AUTOSAR XML (schema 4-2-2)
standard types defined: uint8, uint16, sint8
package /AUTOSAR/Components
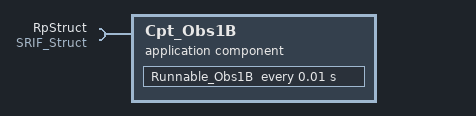
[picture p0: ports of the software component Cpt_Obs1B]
  application sw component type Cpt_Obs1B
    require port RpStruct: nonqueued-receiver-com-spec{data-element=dataElementsStructA, init-value=fields=[0, 1, 2, 0]}, required-interface=SRIF_Struct
    behavior IbObs1B
      timing event timingEvent_10: start-on-event=Runnable_Obs1B, period=0.01
      runnable Runnable_Obs1B: symbol=AppRunnable_Obs1
        data-read-access:
          access dataReadAccess_StructA: accessed-variable=RpStruct.dataElementsStructA
package /AUTOSAR/Compositions
  composition sw component type BottomComposition
    component Cpt_Obs1B_Prototype: type=Cpt_Obs1B
  composition sw component type TopComposition
    component BottomComposition: type=BottomComposition
package /AUTOSAR/SwcImplementations
  swc implementation swcImplementation_CptObs1B: behavior=IbObs1B
package /AUTOSAR/System
  system system_0
    system mapping SystemMapping_0: sender-receiver-to-signal-group-mapping{data-element=BottomComposition.Cpt_Obs1B_Prototype.rootSwCompositionPrototype_0.RpStruct.dataElementsStructA, signal-group=Group_StructA_Msg_StructA, type-mapping=sender-rec-record-type-mapping=record-element-mappings=[{implementation-record-element=Crc_Uint8, system-signal=Signal_DATA8_Msg_StructA}, {implementation-record-element=Data_Uint16, system-signal=Signal_Counter_Msg_StructA}, {implementation-record-element=Counter_Uint8, system-signal=Signal_CRC_Msg_StructA}, {implementation-record-element=Data_Uint8, system-signal=Signal_DATA16_Msg_StructA}]}
      sw-impl-mappings:
        swc to impl mapping CptObs1PrototypeImplMapping: component-implementation=swcImplementation_CptObs1B, component=rootSwCompositionPrototype_0.BottomComposition.Cpt_Obs1B_Prototype.Cpt_Obs1B_Prototype
      sw-mappings:
        swc to ecu mapping ECUB_SwcToEcuMapping: component=rootSwCompositionPrototype_0.BottomComposition.Cpt_Obs1B_Prototype.Cpt_Obs1B_Prototype, ecu-instance=ECUB
    root-software-compositions:
      root sw composition prototype rootSwCompositionPrototype_0: software-composition=TopComposition
package /AUTOSAR/Interfaces
  sender receiver interface SRIF_Struct
    data dataElementsStructA: type=StructA
package /AUTOSAR/DataTypes
  impl type StructA: category=STRUCTURE
    4 x element, all with category=VALUE:
      Crc_Uint8: base-type=uint8
      Data_Uint16: base-type=uint16
      Counter_Uint8: base-type=uint8
      Data_Uint8: base-type=uint8
package /SystemInfo/EcuInstances
  ecu instance ECUB: com-configuration-gw-time-base=0.005, com-configuration-rx-time-base=0.005, com-configuration-tx-time-base=0.005, sleep-mode-supported=false, wake-up-over-bus-supported=false
    can communication controller CanChannel_0_ECUB: wake-up-by-controller-supported=false, can-controller-attributes=can-controller-configuration={sync-jump-width=0, time-seg-1=20, time-seg-2=10}
    can communication connector CanChannel_0_ECUB_conn: comm-controller=CanChannel_0_ECUB
package /SystemInfo/ISignals
  i signal group Group_StructA_Msg_StructA: i-signal=[Signal_DATA8_Msg_StructA, Signal_Counter_Msg_StructA, Signal_CRC_Msg_StructA, Signal_DATA16_Msg_StructA], system-signal-group=Group_StructA_Msg_StructA
package /SystemInfo/CanClusters
  can cluster CanCluster_0: protocol-name=CAN
    can physical channel CanChannel_0: comm-connectors=CanChannel_0_ECUB_conn
      frame Msg_StructA: id 0x302, to ECUB, frame-length=8, can-addressing-mode=STANDARD
        pdu Msg_StructA: length=8, transmission-mode-conditions=[Signal_DATA8_Msg_StructA, Signal_DATA16_Msg_StructA, Signal_Counter_Msg_StructA, Signal_CRC_Msg_StructA], transmission-mode-true-timing=cyclic-timing=time-period=0.1
          mapping Group_StructA_Msg_StructA: i-signal-group=Group_StructA_Msg_StructA, update-indication-bit-position=-1
          signal Signal_DATA16_Msg_StructA: start 24, 16 bit, big-endian, base-type=uint16, update-indication-bit-position=-1, to ECUB
          signal Signal_Counter_Msg_StructA: start 12, 4 bit, big-endian, base-type=uint8, update-indication-bit-position=-1, to ECUB
          signal Signal_DATA8_Msg_StructA: start 32, 8 bit, little-endian, base-type=sint8, update-indication-bit-position=-1, to ECUB
          signal Signal_CRC_Msg_StructA: start 0, 8 bit, big-endian, base-type=uint8, update-indication-bit-position=-1, to ECUB
